# ATmega2560 register map
File version: 1.0
Registers are 8-bit, read-write, reset 0x0 unless marked. A register's access mark holds for its fields unless they carry their own. Offsets are from the block's base; [hi:lo] are bit positions; {n}, {i} and the like mark numbered series.

## TC3 — Timer/Counter, 16-bit
Base 0x00800000
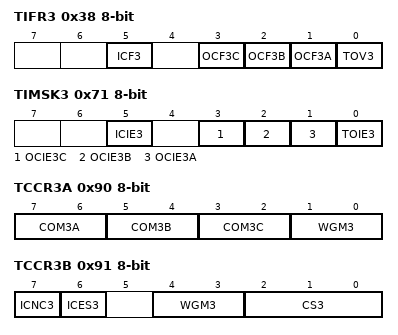
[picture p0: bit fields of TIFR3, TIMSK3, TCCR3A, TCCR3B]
0x38 TIFR3 — Timer/Counter3 Interrupt Flag register
  [5] ICF3 — Input Capture Flag 3
  [3] OCF3C — Output Compare Flag 3C
  [2] OCF3B — Output Compare Flag 3B
  [1] OCF3A — Output Compare Flag 3A
  [0] TOV3 — Timer/Counter3 Overflow Flag
0x71 TIMSK3 — Timer/Counter3 Interrupt Mask Register
  [5] ICIE3 — Timer/Counter3 Input Capture Interrupt Enable
  [3] OCIE3C — Timer/Counter3 Output Compare C Match Interrupt Enable
  [2] OCIE3B — Timer/Counter3 Output Compare B Match Interrupt Enable
  [1] OCIE3A — Timer/Counter3 Output Compare A Match Interrupt Enable
  [0] TOIE3 — Timer/Counter3 Overflow Interrupt Enable
0x90 TCCR3A — Timer/Counter3 Control Register A
  [7:6] COM3A — Compare Output Mode 1A, bits
  [5:4] COM3B — Compare Output Mode 3B, bits
  [3:2] COM3C — Compare Output Mode 3C, bits
  [1:0] WGM3 — Waveform Generation Mode
0x91 TCCR3B — Timer/Counter3 Control Register B
  [7] ICNC3 — Input Capture 3 Noise Canceler
  [6] ICES3 — Input Capture 3 Edge Select
  [4:3] WGM3 — Waveform Generation Mode
  [2:0] CS3 — Prescaler source of Timer/Counter 3
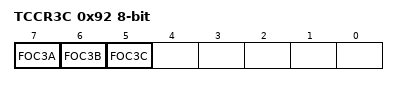
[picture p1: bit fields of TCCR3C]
0x92 TCCR3C — Timer/Counter 3 Control Register C
  [7] FOC3A — Force Output Compare 3A
  [6] FOC3B — Force Output Compare 3B
  [5] FOC3C — Force Output Compare 3C
0x94 TCNT3 16-bit (reset mask 0xFF) — Timer/Counter3 Bytes
0x96 ICR3 16-bit (reset mask 0xFF) — Timer/Counter3 Input Capture Register Bytes
0x98 OCR3A 16-bit (reset mask 0xFF) — Timer/Counter3 Output Compare Register A Bytes
0x9A OCR3B 16-bit (reset mask 0xFF) — Timer/Counter3 Output Compare Register B Bytes
0x9C OCR3C 16-bit (reset mask 0xFF) — Timer/Counter3 Output Compare Register B Bytes

## TC1 — Timer/Counter, 16-bit
Base 0x00800000
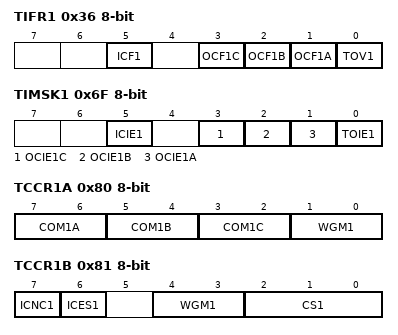
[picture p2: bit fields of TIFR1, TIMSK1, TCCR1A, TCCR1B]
0x36 TIFR1 — Timer/Counter1 Interrupt Flag register
  [5] ICF1 — Input Capture Flag 1
  [3] OCF1C — Output Compare Flag 1C
  [2] OCF1B — Output Compare Flag 1B
  [1] OCF1A — Output Compare Flag 1A
  [0] TOV1 — Timer/Counter1 Overflow Flag
0x6F TIMSK1 — Timer/Counter1 Interrupt Mask Register
  [5] ICIE1 — Timer/Counter1 Input Capture Interrupt Enable
  [3] OCIE1C — Timer/Counter1 Output Compare C Match Interrupt Enable
  [2] OCIE1B — Timer/Counter1 Output Compare B Match Interrupt Enable
  [1] OCIE1A — Timer/Counter1 Output Compare A Match Interrupt Enable
  [0] TOIE1 — Timer/Counter1 Overflow Interrupt Enable
0x80 TCCR1A — Timer/Counter1 Control Register A
  [7:6] COM1A — Compare Output Mode 1A, bits
  [5:4] COM1B — Compare Output Mode 1B, bits
  [3:2] COM1C — Compare Output Mode 1C, bits
  [1:0] WGM1 — Waveform Generation Mode
0x81 TCCR1B — Timer/Counter1 Control Register B
  [7] ICNC1 — Input Capture 1 Noise Canceler
  [6] ICES1 — Input Capture 1 Edge Select
  [4:3] WGM1 — Waveform Generation Mode
  [2:0] CS1 — Prescaler source of Timer/Counter 1
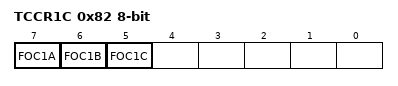
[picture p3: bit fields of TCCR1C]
0x82 TCCR1C — Timer/Counter 1 Control Register C
  [7] FOC1A — Force Output Compare 1A
  [6] FOC1B — Force Output Compare 1B
  [5] FOC1C — Force Output Compare 1C
0x84 TCNT1 16-bit (reset mask 0xFF) — Timer/Counter1 Bytes
0x86 ICR1 16-bit (reset mask 0xFF) — Timer/Counter1 Input Capture Register Bytes
0x88 OCR1A 16-bit (reset mask 0xFF) — Timer/Counter1 Output Compare Register A Bytes
0x8A OCR1B 16-bit (reset mask 0xFF) — Timer/Counter1 Output Compare Register B Bytes
0x8C OCR1C 16-bit (reset mask 0xFF) — Timer/Counter1 Output Compare Register C Bytes

## EXINT — External Interrupts
Base 0x00800000
0x3B PCIFR — Pin Change Interrupt Flag Register
  [2:0] PCIF — Pin Change Interrupt Flags
0x3C EIFR — External Interrupt Flag Register
  [7:0] INTF — External Interrupt Flags
0x3D EIMSK — External Interrupt Mask Register
  [7:0] INT — External Interrupt Request 7 Enable

## EXINT_2 — External Interrupts
Base 0x00800000
0x68 PCICR — Pin Change Interrupt Control Register
  [2:0] PCIE — Pin Change Interrupt Enables
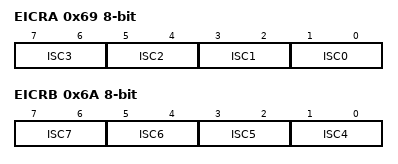
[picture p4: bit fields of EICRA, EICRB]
0x69 EICRA — External Interrupt Control Register A
  [2n+1:2n] ISC{n} (n=0..3) — External Interrupt Sense Control Bit
0x6A EICRB — External Interrupt Control Register B
  [2n-7:2n-8] ISC{n} (n=4..7) — External Interrupt 7-4 Sense Control Bit
{0x6B+i} PCMSK{i} (i=0..2) — Pin Change Mask Register {i}
  [7:0] PCINT — Pin Change Mask interrupt

## ADC — Analog-to-Digital Converter
Base 0x00800000
0x78 ADC 16-bit (reset mask 0xFF) — ADC Data Register Bytes
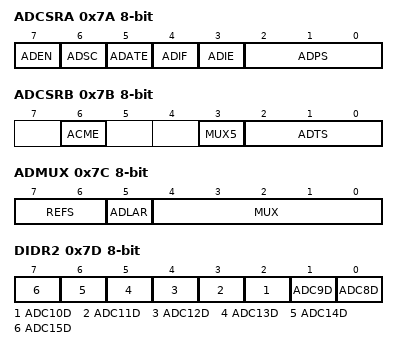
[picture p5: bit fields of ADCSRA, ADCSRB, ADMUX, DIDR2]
0x7A ADCSRA — The ADC Control and Status register A
  [7] ADEN — ADC Enable
  [6] ADSC — ADC Start Conversion
  [5] ADATE — ADC Auto Trigger Enable
  [4] ADIF — ADC Interrupt Flag
  [3] ADIE — ADC Interrupt Enable
  [2:0] ADPS — ADC Prescaler Select Bits
0x7B ADCSRB — The ADC Control and Status register B
  [6] ACME
  [3] MUX5 — Analog Channel and Gain Selection Bits
  [2:0] ADTS — ADC Auto Trigger Source bits
0x7C ADMUX — The ADC multiplexer Selection Register
  [7:6] REFS — Reference Selection Bits
  [5] ADLAR — Left Adjust Result
  [4:0] MUX — Analog Channel and Gain Selection Bits
0x7D DIDR2 — Digital Input Disable Register
  [n-8] ADC{n}D (n=8..15)
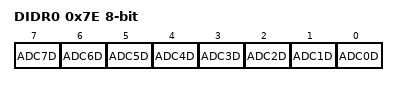
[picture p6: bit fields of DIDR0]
0x7E DIDR0 — Digital Input Disable Register
  [n] ADC{n}D (n=0..7)
